# STM32WL5x_CM0P register map
File version: 1.5
CPU: CM0 r0p1, little endian, MPU, no FPU, 4 interrupt priority bits
Registers are 32-bit, read-write, reset 0x0 unless marked. A register's access mark holds for its fields unless they carry their own. Offsets are from the block's base; [hi:lo] are bit positions; {n}, {i} and the like mark numbered series.

## TAMP — Tamper and backup registers
Base 0x4000B000
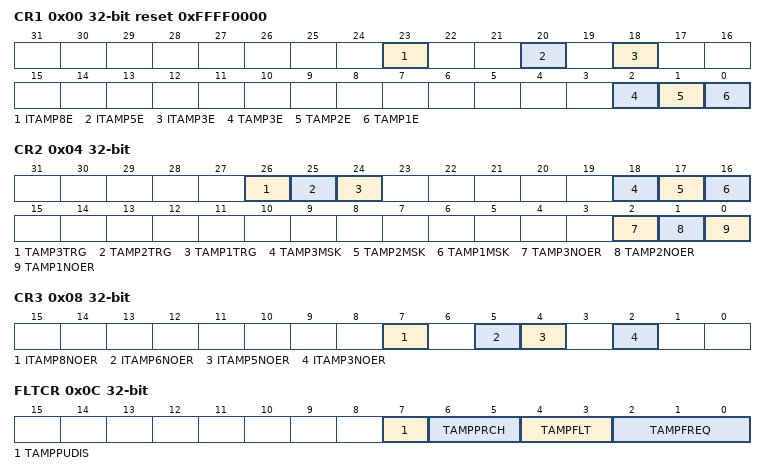
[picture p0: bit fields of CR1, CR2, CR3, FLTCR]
0x00 CR1 reset 0xFFFF0000 — control register 1
  [23] ITAMP8E
  [20] ITAMP5E
  [18] ITAMP3E
  [2] TAMP3E — TAMP2E
  [1] TAMP2E
  [0] TAMP1E
0x04 CR2 — control register 2
  [26] TAMP3TRG, [25] TAMP2TRG, [24] TAMP1TRG, [18] TAMP3MSK, [17] TAMP2MSK, [16] TAMP1MSK, [2] TAMP3NOER, [1] TAMP2NOER, [0] TAMP1NOER
0x08 CR3 — TAMP control register 3
  [7] ITAMP8NOER, [5] ITAMP6NOER, [4] ITAMP5NOER, [2] ITAMP3NOER
0x0C FLTCR — TAMP filter control register
  [7] TAMPPUDIS, [6:5] TAMPPRCH, [4:3] TAMPFLT, [2:0] TAMPFREQ
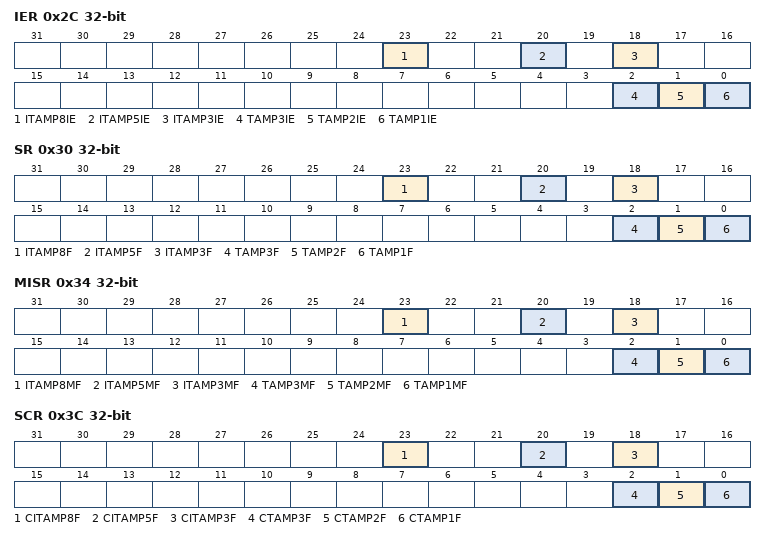
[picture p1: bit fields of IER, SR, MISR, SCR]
0x2C IER — TAMP interrupt enable register
  [23] ITAMP8IE, [20] ITAMP5IE, [18] ITAMP3IE, [2] TAMP3IE, [1] TAMP2IE, [0] TAMP1IE
0x30 SR ro — TAMP status register
  [23] ITAMP8F, [20] ITAMP5F, [18] ITAMP3F, [2] TAMP3F, [1] TAMP2F, [0] TAMP1F
0x34 MISR ro — TAMP masked interrupt status register
  [23] ITAMP8MF, [20] ITAMP5MF, [18] ITAMP3MF, [2] TAMP3MF, [1] TAMP2MF, [0] TAMP1MF
0x3C SCR wo — TAMP status clear register
  [23] CITAMP8F, [20] CITAMP5F, [18] CITAMP3F, [2] CTAMP3F, [1] CTAMP2F, [0] CTAMP1F
0x40 COUNTR ro — monotonic counter register
  [31:0] COUNT
{0x100+4i} BKP{i}R (i=0..9) — TAMP backup register
  [31:0] BKP
{0x118+4i} BKP{i}R (i=10..19) — TAMP backup register
  [31:0] BKP

## MPU — Memory protection unit
Base 0xE000ED90
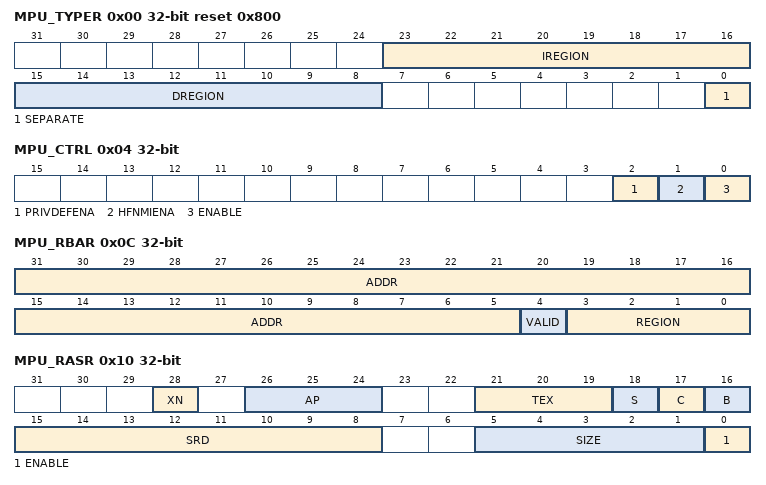
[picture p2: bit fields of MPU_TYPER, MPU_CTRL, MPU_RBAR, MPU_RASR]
0x00 MPU_TYPER ro reset 0x800 — MPU type register
  [23:16] IREGION — Number of MPU instruction regions
  [15:8] DREGION — Number of MPU data regions
  [0] SEPARATE — Separate flag
0x04 MPU_CTRL ro — MPU control register
  [2] PRIVDEFENA — Enable priviliged software access to default memory map
  [1] HFNMIENA — Enables the operation of MPU during hard fault
  [0] ENABLE — Enables the MPU
0x08 MPU_RNR — MPU region number register
  [7:0] REGION — MPU region
0x0C MPU_RBAR — MPU region base address register
  [31:5] ADDR — Region base address field
  [4] VALID — MPU region number valid
  [3:0] REGION — MPU region field
0x10 MPU_RASR — MPU region attribute and size register
  [28] XN — Instruction access disable bit
  [26:24] AP — Access permission
  [21:19] TEX — memory attribute
  [18] S — Shareable memory attribute
  [17] C — memory attribute
  [16] B — memory attribute
  [15:8] SRD — Subregion disable bits
  [5:1] SIZE — Size of the MPU protection region
  [0] ENABLE — Region enable bit.

## STK — SysTick timer
Base 0xE000E010
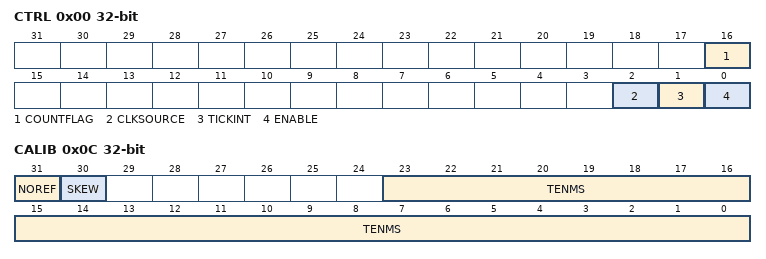
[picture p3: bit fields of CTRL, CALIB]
0x00 CTRL — SysTick control and status register
  [16] COUNTFLAG
  [2] CLKSOURCE — Clock source selection
  [1] TICKINT — SysTick exception request enable
  [0] ENABLE — Counter enable
0x04 LOAD — SysTick reload value register
  [23:0] RELOAD — RELOAD value
0x08 VAL — SysTick current value register
  [23:0] CURRENT — Current counter value
0x0C CALIB — SysTick calibration value register
  [31] NOREF — NOREF flag. Reads as zero
  [30] SKEW — SKEW flag: Indicates whether the TENMS value is exact
  [23:0] TENMS — Calibration value

## NVIC_STIR — Nested vectored interrupt controller
Base 0xE000EF00
0x00 STIR — Software trigger interrupt register
  [8:0] INTID — Software generated interrupt ID

## SCB_ACTRL — System control block ACTLR
Base 0xE000E008
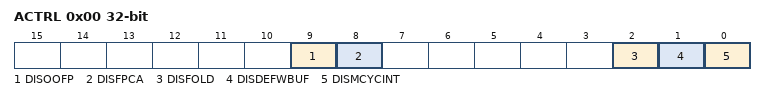
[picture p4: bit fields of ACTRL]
0x00 ACTRL — Auxiliary control register
  [9] DISOOFP, [8] DISFPCA, [2] DISFOLD, [1] DISDEFWBUF, [0] DISMCYCINT

## NVIC — Nested Vectored Interrupt Controller
Base 0xE000E100
0x00 ISER0 — Interrupt Set-Enable Register
  [31:0] SETENA
0x80 ICER0 — Interrupt Clear-Enable Register
  [31:0] CLRENA
0x100 ISPR0 — Interrupt Set-Pending Register
  [31:0] SETPEND
0x180 ICPR0 — Interrupt Clear-Pending Register
  [31:0] CLRPEND
0x200 IABR0 ro — Interrupt Active Bit Register
  [31:0] ACTIVE
0x204 IABR1 ro — Interrupt Active Bit Register
  [31:0] ACTIVE
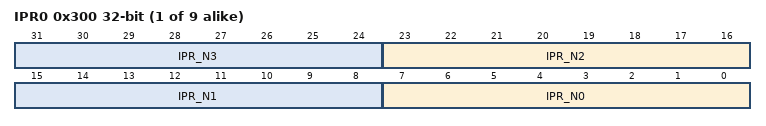
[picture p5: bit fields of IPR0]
{0x300+4i} IPR{i} (i=0..8) — Interrupt Priority Register
  [8n+7:8n] IPR_N{n} (n=0..3)

## DBGMCU — Microcontroller Debug Unit
Base 0xE0042000
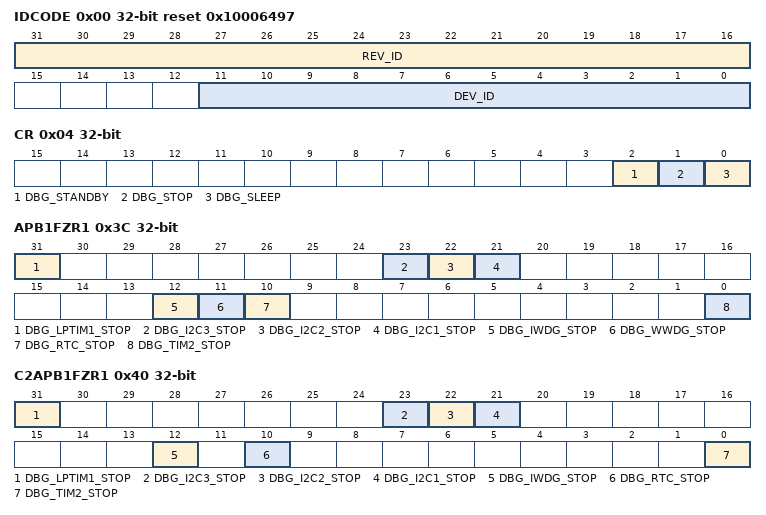
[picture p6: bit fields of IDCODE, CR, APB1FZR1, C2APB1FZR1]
0x00 IDCODE ro reset 0x10006497 — DBGMCU Identity Code Register
  [31:16] REV_ID — Revision
  [11:0] DEV_ID — Device ID
0x04 CR — DBGMCU Configuration Register
  [2] DBG_STANDBY — Allow debug in STANDBY mode
  [1] DBG_STOP — Allow debug in STOP mode
  [0] DBG_SLEEP — Allow debug in SLEEP mode
0x3C APB1FZR1 — DBGMCU CPU1 APB1 Peripheral Freeze Register 1
  [31] DBG_LPTIM1_STOP — LPTIM1 stop in CPU1 debug
  [23] DBG_I2C3_STOP — I2C3 SMBUS timeout stop in CPU1 debug
  [22] DBG_I2C2_STOP — I2C2 SMBUS timeout stop in CPU1 debug
  [21] DBG_I2C1_STOP — I2C1 SMBUS timeout stop in CPU1 debug
  [12] DBG_IWDG_STOP — IWDG stop in CPU1 debug
  [11] DBG_WWDG_STOP — WWDG stop in CPU1 debug
  [10] DBG_RTC_STOP — RTC stop in CPU1 debug
  [0] DBG_TIM2_STOP — TIM2 stop in CPU1 debug
0x40 C2APB1FZR1 — DBGMCU CPU2 APB1 Peripheral Freeze Register 1 [dual core device
  [31] DBG_LPTIM1_STOP, [23] DBG_I2C3_STOP, [22] DBG_I2C2_STOP, [21] DBG_I2C1_STOP, [12] DBG_IWDG_STOP, [10] DBG_RTC_STOP, [0] DBG_TIM2_STOP
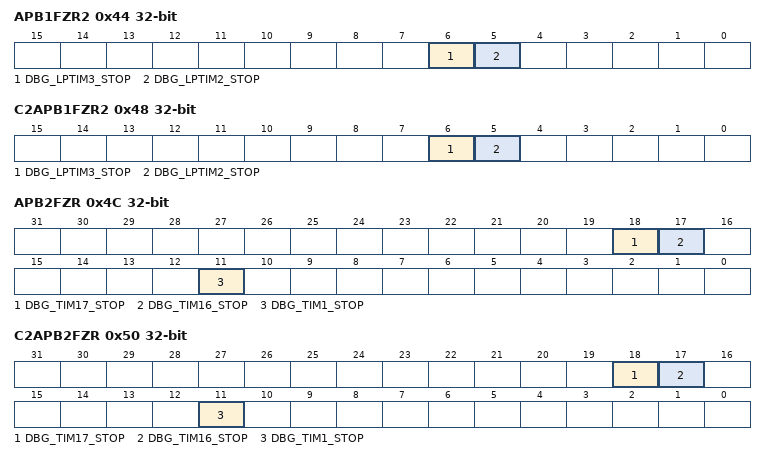
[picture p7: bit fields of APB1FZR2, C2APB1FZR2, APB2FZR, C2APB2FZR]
0x44 APB1FZR2 — DBGMCU CPU1 APB1 Peripheral Freeze Register 2
  [6] DBG_LPTIM3_STOP, [5] DBG_LPTIM2_STOP
0x48 C2APB1FZR2 — DBGMCU CPU2 APB1 Peripheral Freeze Register 2 [dual core device
  [6] DBG_LPTIM3_STOP, [5] DBG_LPTIM2_STOP
0x4C APB2FZR — DBGMCU CPU1 APB2 Peripheral Freeze Register
  [18] DBG_TIM17_STOP, [17] DBG_TIM16_STOP, [11] DBG_TIM1_STOP
0x50 C2APB2FZR — DBGMCU CPU2 APB2 Peripheral Freeze Register [dual core device
  [18] DBG_TIM17_STOP, [17] DBG_TIM16_STOP, [11] DBG_TIM1_STOP

## SYSCFG_continue — System configuration controller
Base 0x40010100
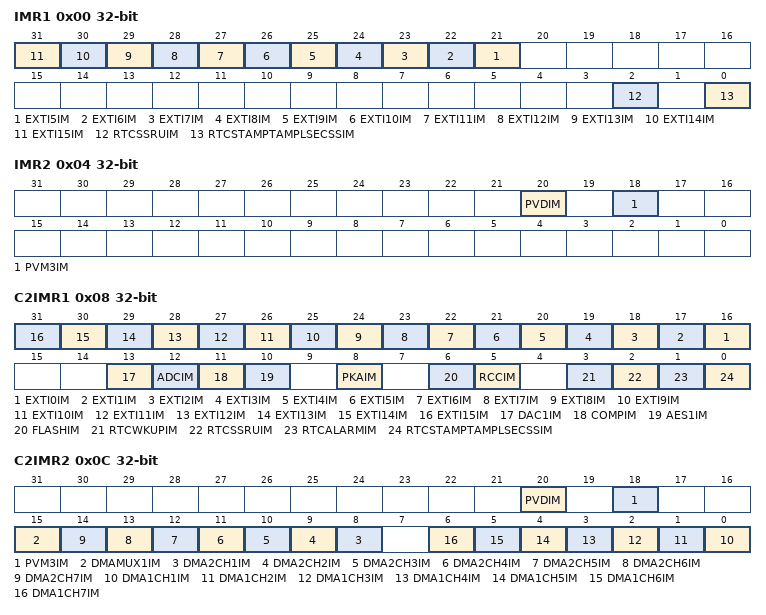
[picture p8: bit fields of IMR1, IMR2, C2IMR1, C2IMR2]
0x00 IMR1
  [n+16] EXTI{n}IM (n=5..15) — Peripheral EXTI{n} interrupt mask to CPU1
  [2] RTCSSRUIM
  [0] RTCSTAMPTAMPLSECSSIM
0x04 IMR2
  [20] PVDIM — Peripheral xxx interrupt mask to CPU1
  [18] PVM3IM — Peripheral xxx interrupt mask to CPU1
0x08 C2IMR1
  [n+16] EXTI{n}IM (n=0..15) — Peripheral EXTI{n} interrupt mask to CPU2
  [13] DAC1IM — Peripheral DAC1 interrupt mask to CPU2
  [12] ADCIM — Peripheral ADC interrupt mask to CPU2
  [11] COMPIM — Peripheral COMP interrupt mask to CPU2
  [10] AES1IM
  [8] PKAIM
  [6] FLASHIM — Peripheral FLASH interrupt mask to CPU2
  [5] RCCIM — Peripheral RCC interrupt mask to CPU2
  [3] RTCWKUPIM — Peripheral RTCWKUP interrupt mask to CPU2
  [2] RTCSSRUIM
  [1] RTCALARMIM — Peripheral RTCALARM interrupt mask to CPU2
  [0] RTCSTAMPTAMPLSECSSIM — Peripheral RTCSTAMPTAMPLSECSS interrupt mask to CPU2
0x0C C2IMR2
  [20] PVDIM — Peripheral PVD interrupt mask to CPU2
  [18] PVM3IM — Peripheral PVM3 interrupt mask to CPU2
  [15] DMAMUX1IM — Peripheral DMAMUX1 interrupt mask to CPU2
  [n+7] DMA2CH{n}IM (n=1..7) — Peripheral DMA2CH{n} interrupt mask to CPU2
  [n-1] DMA1CH{n}IM (n=1..7) — Peripheral DMA1CH{n} interrupt mask to CPU2
